# SIBG301M114KIH register map
Vendor: Silicon Labs; Series: Si; File version: B
Registers are 32-bit, read-write, reset 0x0 unless marked. A register's access mark holds for its fields unless they carry their own. Offsets are from the block's base; [hi:lo] are bit positions; {n}, {i} and the like mark numbered series; 'fields as' and 'values as' point back to an identical list.

## SMU_NS — SMU_NS Registers
Base 0x41008000
Same registers: SMU_S 0x51008000
0x00 IPVERSION ro reset 0x8
0x04 STATUS ro
  [0] SMULOCK
    0=UNLOCKED; 1=LOCKED
0x08 LOCK wo
  [23:0] SMULOCKKEY
    0xACCE55=UNLOCK (Unlocks Registers)
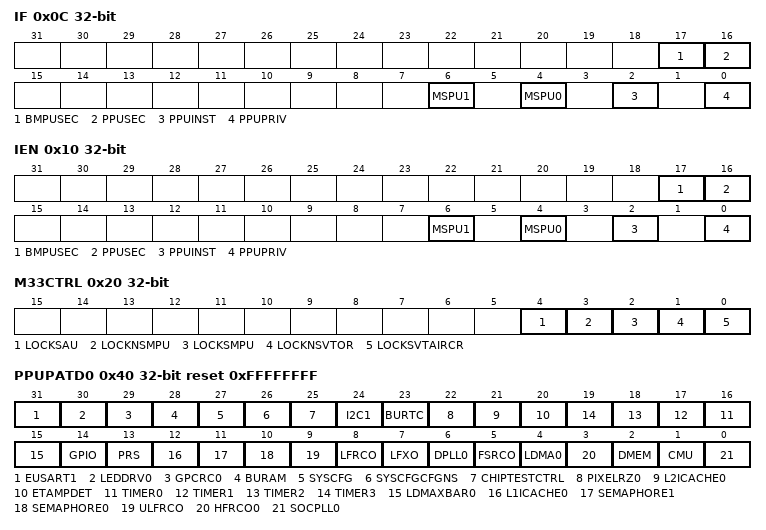
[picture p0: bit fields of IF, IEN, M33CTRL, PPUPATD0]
0x0C IF
  [17] BMPUSEC — BMPU Security Interrupt Flag
  [16] PPUSEC — PPU Security Interrupt Flag
  [6] MSPU1 — NVM MSPU Interrupt Flag
  [4] MSPU0 — DMEM MSPU Interrupt Flag
  [2] PPUINST — PPU Instruction Interrupt Flag
  [0] PPUPRIV — PPU Privilege Interrupt Flag
0x10 IEN
  [17] BMPUSEC — BMPU Security Interrupt Enable
  [16] PPUSEC — PPU Security Interrupt Enable
  [6] MSPU1 — NVM MSPU Interrupt Enable
  [4] MSPU0 — DMEM MSPU Interrupt Enable
  [2] PPUINST — PPU Instruction Interrupt Enable
  [0] PPUPRIV — PPU Privilege Interrupt Enable
0x20 M33CTRL — Holds the M33 control settings
  [4] LOCKSAU
  [3] LOCKNSMPU — Lock Non-secure MPU configuration
  [2] LOCKSMPU — Lock Secure MPU configuration
  [1] LOCKNSVTOR — Lock Non-secure VTOR
  [0] LOCKSVTAIRCR — Lock Secure VTAIRCR
0x40 PPUPATD0 reset 0xFFFFFFFF — Set peripheral bits to 1 to mark as privileged access only
  [31] EUSART1 — EUSART1 Privileged Access
  [30] LEDDRV0 — LEDDRV0 Privileged Access
  [29] GPCRC0 — GPCRC0 Privileged Access
  [28] BURAM — BURAM Privileged Access
  [27] SYSCFG — SYSCFG Privileged Access
  [26] SYSCFGCFGNS — SYSCFGCFGNS Privileged Access
  [25] CHIPTESTCTRL — CHIPTESTCTRL Privileged Access
  [24] I2C1 — I2C1 Privileged Access
  [23] BURTC — BURTC Privileged Access
  [22] PIXELRZ0 — PIXELRZ0 Privileged Access
  [21] L2ICACHE0 — L2ICACHE0 Privileged Access
  [20] ETAMPDET — ETAMPDET Privileged Access
  [n+16] TIMER{n} (n=0..3) — TIMER{n} Privileged Access
  [15] LDMAXBAR0 — LDMAXBAR0 Privileged Access
  [14] GPIO — GPIO Privileged Access
  [13] PRS — PRS Privileged Access
  [12] L1ICACHE0 — L1ICACHE0 Privileged Access
  [11] SEMAPHORE1 — SEMAPHORE1 Privileged Access
  [10] SEMAPHORE0 — SEMAPHORE0 Privileged Access
  [9] ULFRCO — ULFRCO Privileged Access
  [8] LFRCO — LFRCO Privileged Access
  [7] LFXO — LFXO Privileged Access
  [6] DPLL0 — DPLL0 Privileged Access
  [5] FSRCO — FSRCO Privileged Access
  [4] LDMA0 — LDMA0 Privileged Access
  [3] HFRCO0 — HFRCO0 Privileged Access
  [2] DMEM — DMEM Privileged Access
  [1] CMU — CMU Privileged Access
  [0] SOCPLL0 — SOCPLL0 Privileged Access
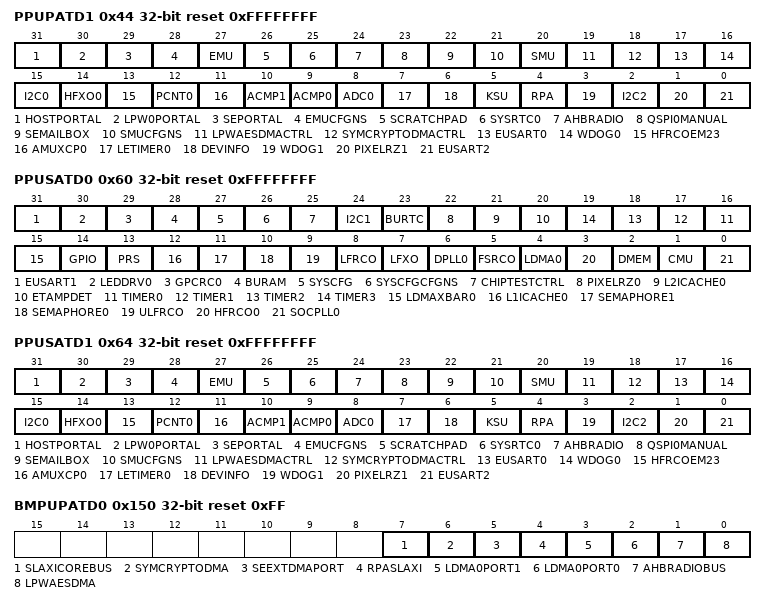
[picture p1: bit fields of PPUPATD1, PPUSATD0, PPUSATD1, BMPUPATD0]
0x44 PPUPATD1 reset 0xFFFFFFFF — Set peripheral bits to 1 to mark as privileged access only
  [31] HOSTPORTAL — HOSTPORTAL Privileged Access
  [30] LPW0PORTAL — LPW0PORTAL Privileged Access
  [29] SEPORTAL — SEPORTAL Privileged Access
  [28] EMUCFGNS — EMUCFGNS Privileged Access
  [27] EMU — EMU Privileged Access
  [26] SCRATCHPAD — SCRATCHPAD Privileged Access
  [25] SYSRTC0 — SYSRTC0 Privileged Access
  [24] AHBRADIO — AHBRADIO Privileged Access
  [23] QSPI0MANUAL — QSPI0MANUAL Privileged Access
  [22] SEMAILBOX — SEMAILBOX Privileged Access
  [21] SMUCFGNS — SMUCFGNS Privileged Access
  [20] SMU — SMU Privileged Access
  [19] LPWAESDMACTRL — LPWAESDMACTRL Privileged Access
  [18] SYMCRYPTODMACTRL — SYMCRYPTODMACTRL Privileged Access
  [17] EUSART0 — EUSART0 Privileged Access
  [16] WDOG0 — WDOG0 Privileged Access
  [15] I2C0 — I2C0 Privileged Access
  [14] HFXO0 — HFXO0 Privileged Access
  [13] HFRCOEM23 — HFRCOEM23 Privileged Access
  [12] PCNT0 — PCNT0 Privileged Access
  [11] AMUXCP0 — AMUXCP0 Privileged Access
  [10] ACMP1 — ACMP1 Privileged Access
  [9] ACMP0 — ACMP0 Privileged Access
  [8] ADC0 — ADC0 Privileged Access
  [7] LETIMER0 — LETIMER0 Privileged Access
  [6] DEVINFO — DEVINFO Privileged Access
  [5] KSU — KSU Privileged Access
  [4] RPA — RPA Privileged Access
  [3] WDOG1 — WDOG1 Privileged Access
  [2] I2C2 — I2C2 Privileged Access
  [1] PIXELRZ1 — PIXELRZ1 Privileged Access
  [0] EUSART2 — EUSART2 Privileged Access
0x60 PPUSATD0 reset 0xFFFFFFFF — Set peripheral bits to 1 to mark as secure access only
  [31] EUSART1 — EUSART1 Secure Access
  [30] LEDDRV0 — LEDDRV0 Secure Access
  [29] GPCRC0 — GPCRC0 Secure Access
  [28] BURAM — BURAM Secure Access
  [27] SYSCFG — SYSCFG Secure Access
  [26] SYSCFGCFGNS — SYSCFGCFGNS Secure Access
  [25] CHIPTESTCTRL — CHIPTESTCTRL Secure Access
  [24] I2C1 — I2C1 Secure Access
  [23] BURTC — BURTC Secure Access
  [22] PIXELRZ0 — PIXELRZ0 Secure Access
  [21] L2ICACHE0 — L2ICACHE0 Secure Access
  [20] ETAMPDET — ETAMPDET Secure Access
  [n+16] TIMER{n} (n=0..3) — TIMER{n} Secure Access
  [15] LDMAXBAR0 — LDMAXBAR0 Secure Access
  [14] GPIO — GPIO Secure Access
  [13] PRS — PRS Secure Access
  [12] L1ICACHE0 — L1ICACHE0 Secure Access
  [11] SEMAPHORE1 — SEMAPHORE1 Secure Access
  [10] SEMAPHORE0 — SEMAPHORE0 Secure Access
  [9] ULFRCO — ULFRCO Secure Access
  [8] LFRCO — LFRCO Secure Access
  [7] LFXO — LFXO Secure Access
  [6] DPLL0 — DPLL0 Secure Access
  [5] FSRCO — FSRCO Secure Access
  [4] LDMA0 — LDMA0 Secure Access
  [3] HFRCO0 — HFRCO0 Secure Access
  [2] DMEM — DMEM Secure Access
  [1] CMU — CMU Secure Access
  [0] SOCPLL0 — SOCPLL0 Secure Access
0x64 PPUSATD1 reset 0xFFFFFFFF — Set peripheral bits to 1 to mark as secure access only
  [31] HOSTPORTAL — HOSTPORTAL Secure Access
  [30] LPW0PORTAL — LPW0PORTAL Secure Access
  [29] SEPORTAL — SEPORTAL Secure Access
  [28] EMUCFGNS — EMUCFGNS Secure Access
  [27] EMU — EMU Secure Access
  [26] SCRATCHPAD — SCRATCHPAD Secure Access
  [25] SYSRTC0 — SYSRTC0 Secure Access
  [24] AHBRADIO — AHBRADIO Secure Access
  [23] QSPI0MANUAL — QSPI0MANUAL Secure Access
  [22] SEMAILBOX — SEMAILBOX Secure Access
  [21] SMUCFGNS — SMUCFGNS Secure Access
  [20] SMU — SMU Secure Access
  [19] LPWAESDMACTRL — LPWAESDMACTRL Secure Access
  [18] SYMCRYPTODMACTRL — SYMCRYPTODMACTRL Secure Access
  [17] EUSART0 — EUSART0 Secure Access
  [16] WDOG0 — WDOG0 Secure Access
  [15] I2C0 — I2C0 Secure Access
  [14] HFXO0 — HFXO0 Secure Access
  [13] HFRCOEM23 — HFRCOEM23 Secure Access
  [12] PCNT0 — PCNT0 Secure Access
  [11] AMUXCP0 — AMUXCP0 Secure Access
  [10] ACMP1 — ACMP1 Secure Access
  [9] ACMP0 — ACMP0 Secure Access
  [8] ADC0 — ADC0 Secure Access
  [7] LETIMER0 — LETIMER0 Secure Access
  [6] DEVINFO — DEVINFO Secure Access
  [5] KSU — KSU Secure Access
  [4] RPA — RPA Secure Access
  [3] WDOG1 — WDOG1 Secure Access
  [2] I2C2 — I2C2 Secure Access
  [1] PIXELRZ1 — PIXELRZ1 Secure Access
  [0] EUSART2 — EUSART2 Secure Access
0x130 PPURSPERRD — Set to 1 to response with error or 0 to response with RAZ and WI
  [0] PPURSPERRD — PPU Respond with Error
0x140 PPUFS ro
  [7:0] PPUFSPERIPHID — Peripheral ID
0x144 PPUFSADDR ro
  [31:0] PPUFSADDR — Fault Address
0x150 BMPUPATD0 reset 0xFF — Set master bits to 1 to mark as a privileged master
  [7] SLAXICOREBUS — SLAXICOREBUS Privileged Mode
  [6] SYMCRYPTODMA — SYMCRYPTODMA Privileged Mode
  [5] SEEXTDMAPORT — SEEXTDMAPORT Privileged Mode
  [4] RPASLAXI — RPASLAXI Privileged Mode
  [3] LDMA0PORT1 — LDMA0PORT1 Privileged Mode
  [2] LDMA0PORT0 — LDMA0PORT0 Privileged Mode
  [1] AHBRADIOBUS — AHBRADIOBUS Privileged Mode
  [0] LPWAESDMA — LPWAESDMA Privileged Mode
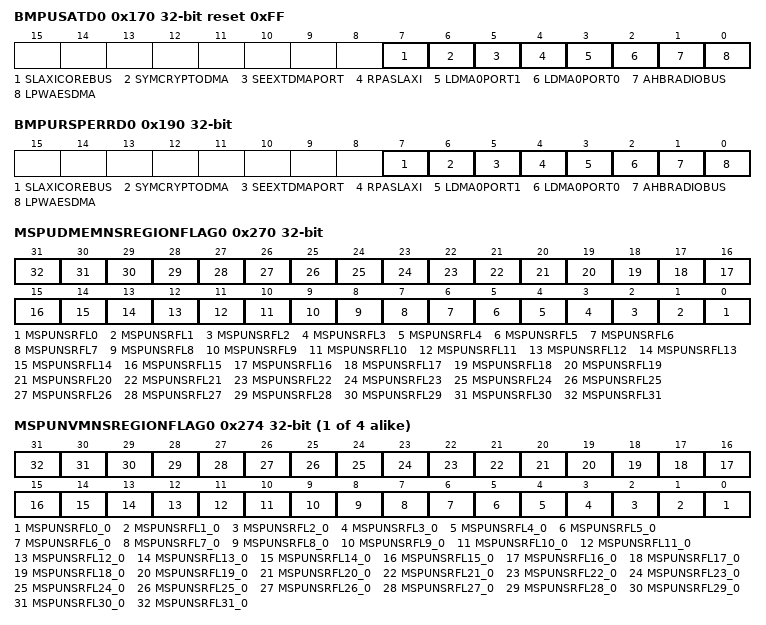
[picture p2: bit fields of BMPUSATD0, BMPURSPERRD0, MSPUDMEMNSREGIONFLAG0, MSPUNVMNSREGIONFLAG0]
0x170 BMPUSATD0 reset 0xFF — Set master bits to 1 to mark as a secure master
  [7] SLAXICOREBUS — SLAXICOREBUS Secure Mode
  [6] SYMCRYPTODMA — SYMCRYPTODMA Secure Mode
  [5] SEEXTDMAPORT — SEEXTDMAPORT Secure Mode
  [4] RPASLAXI — RPASLAXI Secure Mode
  [3] LDMA0PORT1 — LDMA0PORT1 Secure Mode
  [2] LDMA0PORT0 — LDMA0PORT0 Secure Mode
  [1] AHBRADIOBUS — AHBRADIOBUS Secure Mode
  [0] LPWAESDMA — LPWAESDMA Secure Mode
0x190 BMPURSPERRD0 — Set to 1 to response with error or 0 to response with RAZ and WI
  [7] SLAXICOREBUS — SLAXICOREBUS Respond with Error
  [6] SYMCRYPTODMA — SYMCRYPTODMA Respond with Error
  [5] SEEXTDMAPORT — SEEXTDMAPORT Respond with Error
  [4] RPASLAXI — RPASLAXI Respond with Error
  [3] LDMA0PORT1 — LDMA0PORT1 Respond with Error
  [2] LDMA0PORT0 — LDMA0PORT0 Respond with Error
  [1] AHBRADIOBUS — AHBRADIOBUS Respond with Error
  [0] LPWAESDMA — LPWAESDMA Respond with Error
0x250 BMPUFS ro
  [7:0] BMPUFSMASTERID — Bus Manager ID
0x254 BMPUFSADDR ro
  [31:0] BMPUFSADDR — Fault Address
0x260 MSPUDMEMREGIONSIZE — 3 bits control region size of DMEM MSPU
  [2:0] MSPURSIZE — Region Size configuration
    0=MSPU_16KB; 1=MSPU_32KB; 2=MSPU_64KB; 3=MSPU_128KB; 4=MSPU_256KB; 5=MSPU_512KB
0x264 MSPUNVMREGIONSIZE — 3 bits control region size of NVM MSPU
  fields as MSPUDMEMREGIONSIZE
0x268 MSPUDMEMRSPERRD reset 0x1 — Set to 1 to response with error or 0 to response with RAZ and WI of DMEM MSPU
  [0] MSPURSPERRD0 — DMEM MSPU Respond with Error
0x26C MSPUNVMRSPERRD reset 0x1 — Set to 1 to response with error or 0 to response with RAZ and WI of NVM MSPU
  [0] MSPURSPERRD0 — NVM MSPU Respond with Error
0x270 MSPUDMEMNSREGIONFLAG0 — Set to 0 as a secure and set to 1 as a nonsecure per DMEM Region
  [n] MSPUNSRFL{n} (n=0..31) — DMEM non-secure region flags
{0x274+4i} MSPUNVMNSREGIONFLAG{i} (i=0..3) — Set to 0 as a secure and set to 1 as a nonsecure per NVM Region
  [n] MSPUNSRFL{n}_{i} (n=0..31) — NVM non-secure region flags
0x360 MSPUDMEMFSADDR ro
  [31:0] MSPUFSADDR — Fault Address
0x364 MSPUNVMFSADDR ro
  [31:0] MSPUFSADDR — Fault Address
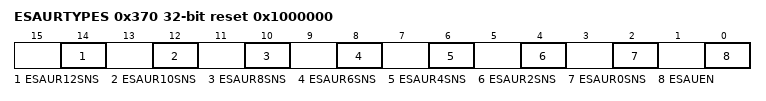
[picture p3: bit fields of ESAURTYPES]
0x370 ESAURTYPES reset 0x1000000
  [14] ESAUR12SNS — Region 12/13 Non-Secure-Callable
  [12] ESAUR10SNS — Region 10/11 Non-Secure-Callable
  [10] ESAUR8SNS — Region 8/9 Non-Secure-Callable
  [8] ESAUR6SNS — Region 6/7 Non-Secure-Callable
  [6] ESAUR4SNS — Region 4/5 Non-Secure-Callable
  [4] ESAUR2SNS — Region 2/3 Non-Secure-Callable
  [2] ESAUR0SNS — Region 0/1 Non-Secure-Callable
  [0] ESAUEN — ESAU enable
